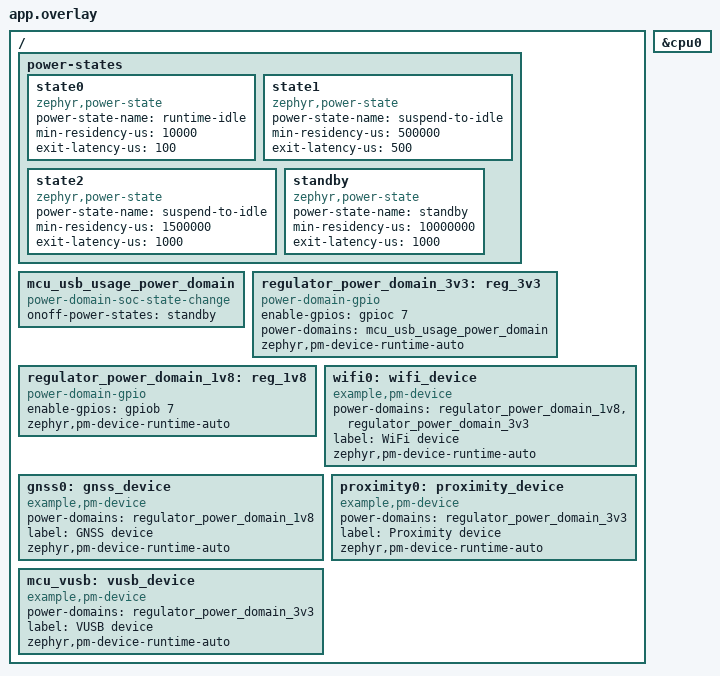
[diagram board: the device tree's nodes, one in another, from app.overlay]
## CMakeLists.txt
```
# SPDX-License-Identifier: Apache-2.0

cmake_minimum_required(VERSION 3.20.0)

set(EXTRA_ZEPHYR_MODULES $ENV{ZEPHYR_BASE}/../sample_device)

find_package(Zephyr REQUIRED HINTS $ENV{ZEPHYR_BASE})
project(hello_world)

message(WARNING " === $ENV{ZEPHYR_BASE}/../sample_device")


target_sources(app PRIVATE
        src/main.c
        src/pm_notifier.c
)
```

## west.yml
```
manifest:
        remotes:
                - name: zephyrproject-rtos
                  url-base: https://github.com/zephyrproject-rtos

        projects:
                - name: zview
                  url: https://github.com/wkhadgar/zview
                  revision: v0.13.0
                  path: modules/tools/zview
                  west-commands: scripts/west-commands.yml
                - name: zbook
                  url: https://github.com/zephyr-book/zbook
                  revision: main
                # Local Renode tooling module (web dashboard / GDB debug / run /
                # repl regen) exposing the `west zvb-*` commands. Developed
                # in-tree; the dir already exists, so don't `west update` this
                # project until it is published at the URL below.
                - name: zephyr-virtual-board
                  url: https://github.com/OWNER/zephyr-virtual-board
                  revision: main
                  path: modules/tools/zephyr-virtual-board
                  west-commands: scripts/west-commands.yml
                - name: zephyr
                  url: https://github.com/rodrigopex/zephyr/
                  revision: 93f320d1d6d061f4eda1b74bbbd6891f36a36fb8
                  clone-depth: 1
                  import:
                          # By using name-allowlist we clone only required modules
                          name-allowlist:
                                  - cmsis_6 # ARM CMSIS (required by soc/arm/mps2/soc.h)
                                  - hal_stm32
```

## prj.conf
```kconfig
# nothing here
CONFIG_LOG=y
CONFIG_SHELL=y

# Required by main.c (LED/button) and by the power-domain-gpio driver
# (CONFIG_POWER_DOMAIN_GPIO depends on GPIO); without it the domain devices
# reg_3v3/reg_1v8 are never defined and PM device _domains arrays fail to link.
CONFIG_GPIO=y

CONFIG_PM=y
CONFIG_PM_DEVICE=y
CONFIG_PM_DEVICE_SHELL=y
CONFIG_PM_DEVICE_RUNTIME=y
#CONFIG_PM_DEVICE_SYSTEM_MANAGED=y
CONFIG_PM_DEVICE_POWER_DOMAIN=y
CONFIG_POWER_DOMAIN=y

# Zview requirements
CONFIG_INIT_STACKS=y
CONFIG_THREAD_MONITOR=y
CONFIG_THREAD_STACK_INFO=y
# Optional Features
CONFIG_THREAD_NAME=y            # Enables thread name display
CONFIG_THREAD_RUNTIME_STATS=y   # Enables CPU usage tracking
CONFIG_SYS_HEAP_RUNTIME_STATS=y # Enables heap runtime stats and fragmentation map
```

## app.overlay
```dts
/*
 * Copyright (c) 2026 Rodrigo Peixoto
 * SPDX-License-Identifier: Apache-2.0
 */

/ {

        power-states {
		state0: state0 {
			compatible = "zephyr,power-state";
			power-state-name = "runtime-idle";
			min-residency-us = <10000>;
			exit-latency-us = <100>;
		};

		state1: state1 {
			compatible = "zephyr,power-state";
			power-state-name = "suspend-to-idle";
			min-residency-us = <500000>;
			exit-latency-us = <500>;
		};
		state2: state2 {
			compatible = "zephyr,power-state";
			power-state-name = "suspend-to-idle";
			min-residency-us = <1500000>;
			exit-latency-us = <1000>;
		};

		standby: standby {
			compatible = "zephyr,power-state";
			power-state-name = "standby";
			min-residency-us = <10000000>;
			exit-latency-us = <1000>;
		};
	};
        /* The ../zephyr/dts/arm/st/u5/stm32u5.dtsi declares the power states */
        mcu_usb_usage_power_domain: mcu_usb_usage_power_domain {
                compatible = "power-domain-soc-state-change";
		status = "okay";
		#power-domain-cells = <0>;
		onoff-power-states = <&standby>;
	};

	regulator_power_domain_3v3: reg_3v3 {
		compatible = "power-domain-gpio";
		enable-gpios = <&gpioc 7 GPIO_ACTIVE_HIGH>; /* LED1 */
		status = "okay";
		#power-domain-cells = <0>;
		power-domains = <&mcu_usb_usage_power_domain>;
		zephyr,pm-device-runtime-auto;
	};

	regulator_power_domain_1v8: reg_1v8 {
	        compatible = "power-domain-gpio";
	        enable-gpios = <&gpiob 7 GPIO_ACTIVE_HIGH>; /* LED2 */
	        status = "okay";
		#power-domain-cells = <0>;
		zephyr,pm-device-runtime-auto;
	};

	wifi0: wifi_device {
		compatible = "example,pm-device";
                status = "okay";
		power-domains = <&regulator_power_domain_1v8 &regulator_power_domain_3v3>;
		label = "WiFi device";
		zephyr,pm-device-runtime-auto;
	};
	gnss0: gnss_device {
		compatible = "example,pm-device";
                status = "okay";
		power-domains = <&regulator_power_domain_1v8>;
		label = "GNSS device";
		zephyr,pm-device-runtime-auto;
	};

	proximity0: proximity_device {
		compatible = "example,pm-device";
                status = "okay";
		power-domains = <&regulator_power_domain_3v3>;
		label = "Proximity device";
		zephyr,pm-device-runtime-auto;
	};

	mcu_vusb: vusb_device {
		compatible = "example,pm-device";
                status = "okay";
		power-domains = <&regulator_power_domain_3v3>;
		label = "VUSB device";
		zephyr,pm-device-runtime-auto;
	};
};

/*
 * Board overlay applied ONLY for nucleo_u5a5zj_q (the Renode-emulated board).
 *
 * Renode 1.16.1 models neither the STM32U5 Stop-mode wake timers (LPTIM/RTC)
 * nor Stop-mode SysTick gating. Once Zephyr's PM idle enters a Stop state the
 * kernel tick halts and the emulator freezes (k_sleep never returns). Drop the
 * CPU power-states so the idle stays in plain WFI -- SysTick keeps running and
 * time advances under emulation. Device power-domains (the point of the study)
 * are unaffected; hardware builds (e.g. stm32u5g9j_dk2) keep full CONFIG_PM.
 */

&cpu0 {
	/delete-property/ cpu-power-states;
};
```

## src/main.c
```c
/*
 * Copyright (c) 2026 Rodrigo Peixoto
 *
 * SPDX-License-Identifier: Apache-2.0
 */

#include <stdint.h>
#include <zephyr/kernel.h>
#include <zephyr/drivers/gpio.h>
#include <zephyr/logging/log.h>

LOG_MODULE_REGISTER(hello_world, LOG_LEVEL_INF);

/*
 * red_led_1 = PG2 is the only user LED not claimed by a power-domain
 * (PC7/PB7 are the regulator enables). user_button = PC13, the blue
 * USER button. Both come from the nucleo_u5a5zj_q board devicetree.
 */
static const struct gpio_dt_spec led = GPIO_DT_SPEC_GET(DT_NODELABEL(red_led_1), gpios);
static const struct gpio_dt_spec button = GPIO_DT_SPEC_GET(DT_NODELABEL(user_button), gpios);

static struct gpio_callback button_cb_data;

static int blink_timeout = 0;

static void button_pressed(const struct device *dev, struct gpio_callback *cb, uint32_t pins)
{
	LOG_INF("Button pressed at %" PRIu32, k_cycle_get_32());
	blink_timeout += 1;
	blink_timeout = blink_timeout % 6;
}

int main(void)
{
	if (!gpio_is_ready_dt(&led) || !gpio_is_ready_dt(&button)) {
		LOG_ERR("GPIO not ready");
		return 0;
	}

	gpio_pin_configure_dt(&led, GPIO_OUTPUT_INACTIVE);

	gpio_pin_configure_dt(&button, GPIO_INPUT);
	gpio_pin_interrupt_configure_dt(&button, GPIO_INT_EDGE_TO_ACTIVE);
	gpio_init_callback(&button_cb_data, button_pressed, BIT(button.pin));
	gpio_add_callback_dt(&button, &button_cb_data);

	LOG_INF("Blink demo: red LED (PG2) blinking");
	int count = 0;
	while (1) {
		gpio_pin_toggle_dt(&led);
		if (count == 10) {
			count = 0;
			k_msleep(3000);
		} else {
			k_msleep((blink_timeout + 1) * 250);
		}
		count++;
	}

	return 0;
}
```

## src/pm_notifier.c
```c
#include <zephyr/kernel.h>
#include <zephyr/pm/pm.h>

static const char *const state_names[] = {
	[PM_STATE_ACTIVE] = "ACTIVE",
	[PM_STATE_RUNTIME_IDLE] = "RUNTIME_IDLE",
	[PM_STATE_SUSPEND_TO_IDLE] = "SUSPEND_TO_IDLE",
	[PM_STATE_STANDBY] = "STANDBY",
	[PM_STATE_SUSPEND_TO_RAM] = "SUSPEND_TO_RAM",
	[PM_STATE_SUSPEND_TO_DISK] = "SUSPEND_TO_DISK",
	[PM_STATE_SOFT_OFF] = "SOFT_OFF",
};

static void on_state_entry(enum pm_state state)
{
	/* About to enter `state` (ACTIVE → low-power), just before pm_state_set(). */
	const char *state_str = (state < ARRAY_SIZE(state_names) && state_names[state])
					? state_names[state]
					: "UNKNOWN";

	printk("Entering state %s\n", state_str);
}

static void on_state_exit(enum pm_state state)
{
	/* Just woke from `state` (low-power → ACTIVE) — may run in the wake ISR. */
	const char *state_str = (state < ARRAY_SIZE(state_names) && state_names[state])
					? state_names[state]
					: "UNKNOWN";

	printk("Exiting state %s\n", state_str);
}

static struct pm_notifier notifier = {
	.state_entry = on_state_entry,
	.state_exit = on_state_exit,
	.report_substate = true,
};

int pm_notifier_init(void)
{
	pm_notifier_register(&notifier);
	return 0;
}

SYS_INIT(pm_notifier_init, APPLICATION, 99);
```
